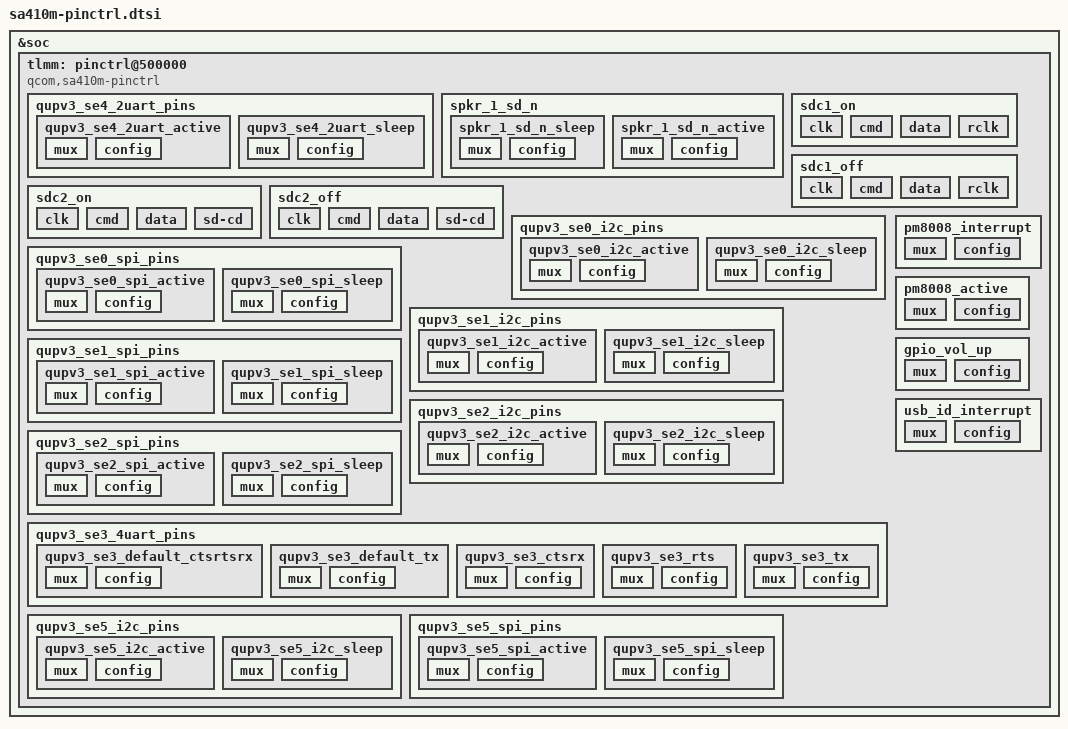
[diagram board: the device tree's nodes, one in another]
&soc {
	tlmm: pinctrl@500000 {
		compatible = "qcom,sa410m-pinctrl";
		reg = <0x500000 0x300000>;
		interrupts = <GIC_SPI 227 IRQ_TYPE_LEVEL_HIGH>;
		gpio-controller;
		#gpio-cells = <2>;
		interrupt-controller;
		#interrupt-cells = <2>;
		wakeup-parent = <&wakegic>;

		qupv3_se4_2uart_pins: qupv3_se4_2uart_pins {
			qupv3_se4_2uart_active: qupv3_se4_2uart_active {
				mux {
					pins = "gpio12", "gpio13";
					function = "qup4";
				};

				config {
					pins = "gpio12", "gpio13";
					drive-strength = <2>;
					bias-disable;
				};
			};

			qupv3_se4_2uart_sleep: qupv3_se4_2uart_sleep {
				mux {
					pins = "gpio12", "gpio13";
					function = "gpio";
				};

				config {
					pins = "gpio12", "gpio13";
					drive-strength = <2>;
					bias-pull-down;
				};
			};
		};

		/* WSA speaker reset pin1 */
		spkr_1_sd_n {
			spkr_1_sd_n_sleep: spkr_1_sd_n_sleep {
				mux {
					pins = "gpio106";
					function = "gpio";
				};

				config {
					pins = "gpio106";
					drive-strength = <2>;   /* 2 mA */
					bias-pull-down;
					input-enable;
				};
			};

			spkr_1_sd_n_active: spkr_1_sd_n_active {
				mux {
					pins = "gpio106";
					function = "gpio";
				};

				config {
					pins = "gpio106";
					drive-strength = <16>;   /* 16 mA */
					bias-disable;
					output-high;
				};
			};
		};

		/* SDC pin type */
		sdc1_on: sdc1_on {
			clk {
				pins = "sdc1_clk";
				bias-disable;
				drive-strength = <16>;
			};

			cmd {
				pins = "sdc1_cmd";
				bias-pull-up;
				drive-strength = <10>;
			};

			data {
				pins = "sdc1_data";
				bias-pull-up;
				drive-strength = <10>;
			};

			rclk {
				pins = "sdc1_rclk";
				bias-pull-down;
			};
		};

		sdc1_off: sdc1_off {
			clk {
				pins = "sdc1_clk";
				bias-disable;
				drive-strength = <2>;
			};

			cmd {
				pins = "sdc1_cmd";
				bias-pull-up;
				drive-strength = <2>;
			};

			data {
				pins = "sdc1_data";
				bias-pull-up;
				drive-strength = <2>;
			};

			rclk {
				pins = "sdc1_rclk";
				bias-pull-down;
			};
		};

		sdc2_on: sdc2_on {
			clk {
				pins = "sdc2_clk";
				bias-disable;
				drive-strength = <16>;
			};

			cmd {
				pins = "sdc2_cmd";
				bias-pull-up;
				drive-strength = <10>;
			};

			data {
				pins = "sdc2_data";
				bias-pull-up;
				drive-strength = <10>;
			};

			sd-cd {
				pins = "gpio88";
				bias-pull-up;
				drive-strength = <2>;
			};
		};

		sdc2_off: sdc2_off {
			clk {
				pins = "sdc2_clk";
				bias-disable;
				drive-strength = <2>;
			};

			cmd {
				pins = "sdc2_cmd";
				bias-pull-up;
				drive-strength = <2>;
			};

			data {
				pins = "sdc2_data";
				bias-pull-up;
				drive-strength = <2>;
			};

			sd-cd {
				pins = "gpio88";
				bias-disable;
				drive-strength = <2>;
			};
		};

		qupv3_se0_i2c_pins: qupv3_se0_i2c_pins {
			qupv3_se0_i2c_active: qupv3_se0_i2c_active {
				mux {
					pins = "gpio0", "gpio1";
					function = "qup0";
				};

				config {
					pins = "gpio0", "gpio1";
					drive-strength = <2>;
					bias-pull-up;
				};
			};

			qupv3_se0_i2c_sleep: qupv3_se0_i2c_sleep {
				mux {
					pins = "gpio0", "gpio1";
					function = "gpio";
				};

				config {
					pins = "gpio0", "gpio1";
					drive-strength = <2>;
					bias-disable;
				};
			};
		};

		qupv3_se0_spi_pins: qupv3_se0_spi_pins {
			qupv3_se0_spi_active: qupv3_se0_spi_active {
				mux {
					pins = "gpio0", "gpio1",
							"gpio2", "gpio3";
					function = "qup0";
				};

				config {
					pins = "gpio0", "gpio1",
							"gpio2", "gpio3";
					drive-strength = <6>;
					bias-disable;
				};
			};

			qupv3_se0_spi_sleep: qupv3_se0_spi_sleep {
				mux {
					pins = "gpio0", "gpio1",
							"gpio2", "gpio3";
					function = "gpio";
				};

				config {
					pins = "gpio0", "gpio1",
							"gpio2", "gpio3";
					drive-strength = <6>;
					bias-disable;
				};
			};
		};

		qupv3_se1_i2c_pins: qupv3_se1_i2c_pins {
			qupv3_se1_i2c_active: qupv3_se1_i2c_active {
				mux {
					pins = "gpio4", "gpio5";
					function = "qup1";
				};

				config {
					pins = "gpio4", "gpio5";
					drive-strength = <2>;
					bias-pull-up;
				};
			};

			qupv3_se1_i2c_sleep: qupv3_se1_i2c_sleep {
				mux {
					pins = "gpio4", "gpio5";
					function = "gpio";
				};

				config {
					pins = "gpio4", "gpio5";
					drive-strength = <2>;
					bias-disable;
				};
			};
		};

		qupv3_se1_spi_pins: qupv3_se1_spi_pins {
			qupv3_se1_spi_active: qupv3_se1_spi_active {
				mux {
					pins = "gpio4", "gpio5",
							"gpio69", "gpio70";
					function = "qup1";
				};

				config {
					pins = "gpio4", "gpio5",
							"gpio69", "gpio70";
					drive-strength = <6>;
					bias-disable;
				};
			};

			qupv3_se1_spi_sleep: qupv3_se1_spi_sleep {
				mux {
					pins = "gpio4", "gpio5",
							"gpio69", "gpio70";
					function = "gpio";
				};

				config {
					pins = "gpio4", "gpio5",
							"gpio69", "gpio70";
					drive-strength = <6>;
					bias-disable;
				};
			};
		};

		qupv3_se2_i2c_pins: qupv3_se2_i2c_pins {
			qupv3_se2_i2c_active: qupv3_se2_i2c_active {
				mux {
					pins = "gpio6", "gpio7";
					function = "qup2";
				};

				config {
					pins = "gpio6", "gpio7";
					drive-strength = <2>;
					bias-pull-up;
				};
			};

			qupv3_se2_i2c_sleep: qupv3_se2_i2c_sleep {
				mux {
					pins = "gpio6", "gpio7";
					function = "gpio";
				};

				config {
					pins = "gpio6", "gpio7";
					drive-strength = <2>;
					bias-disable;
				};
			};
		};

		qupv3_se2_spi_pins: qupv3_se2_spi_pins {
			qupv3_se2_spi_active: qupv3_se2_spi_active {
				mux {
					pins = "gpio6", "gpio7",
							"gpio71", "gpio80";
					function = "qup2";
				};

				config {
					pins = "gpio6", "gpio7",
							"gpio71", "gpio80";
					drive-strength = <6>;
					bias-disable;
				};
			};

			qupv3_se2_spi_sleep: qupv3_se2_spi_sleep {
				mux {
					pins = "gpio6", "gpio7",
							"gpio71", "gpio80";
					function = "gpio";
				};

				config {
					pins = "gpio6", "gpio7",
							"gpio71", "gpio80";
					drive-strength = <6>;
					bias-disable;
				};
			};
		};

		qupv3_se3_4uart_pins: qupv3_se3_4uart_pins {
			qupv3_se3_default_ctsrtsrx:
				qupv3_se3_default_ctsrtsrx {
				mux {
					pins = "gpio8", "gpio9", "gpio11";
					function = "gpio";
				};

				config {
					pins = "gpio8", "gpio9", "gpio11";
					drive-strength = <2>;
					bias-pull-down;
				};
			};

			qupv3_se3_default_tx:
				qupv3_se3_default_tx {
				mux {
					pins = "gpio10";
					function = "gpio";
				};

				config {
					pins = "gpio10";
					drive-strength = <2>;
					bias-pull-up;
				};
			};

			qupv3_se3_ctsrx: qupv3_se3_ctsrx {
				mux {
					pins = "gpio8", "gpio11";
					function = "qup3";
				};

				config {
					pins = "gpio8", "gpio11";
					drive-strength = <2>;
					bias-disable;
				};
			};

			qupv3_se3_rts: qupv3_se3_rts {
				mux {
					pins = "gpio9";
					function = "qup3";
				};

				config {
					pins = "gpio9";
					drive-strength = <2>;
					bias-pull-down;
				};
			};

			qupv3_se3_tx: qupv3_se3_tx {
				mux {
					pins = "gpio10";
					function = "qup3";
				};

				config {
					pins = "gpio10";
					drive-strength = <2>;
					bias-pull-up;
				};
			};
		};

		qupv3_se5_i2c_pins: qupv3_se5_i2c_pins {
			qupv3_se5_i2c_active: qupv3_se5_i2c_active {
				mux {
					pins = "gpio14", "gpio15";
					function = "qup5";
				};

				config {
					pins = "gpio14", "gpio15";
					drive-strength = <2>;
					bias-pull-up;
				};
			};

			qupv3_se5_i2c_sleep: qupv3_se5_i2c_sleep {
				mux {
					pins = "gpio14", "gpio15";
					function = "gpio";
				};

				config {
					pins = "gpio14", "gpio15";
					drive-strength = <2>;
					bias-disable;
				};
			};
		};

		qupv3_se5_spi_pins: qupv3_se5_spi_pins {
			qupv3_se5_spi_active: qupv3_se5_spi_active {
				mux {
					pins = "gpio14", "gpio15",
							"gpio16", "gpio17";
					function = "qup5";
				};

				config {
					pins = "gpio14", "gpio15",
							"gpio16", "gpio17";
					drive-strength = <6>;
					bias-disable;
				};
			};

			qupv3_se5_spi_sleep: qupv3_se5_spi_sleep {
				mux {
					pins = "gpio14", "gpio15",
							"gpio16", "gpio17";
					function = "gpio";
				};

				config {
					pins = "gpio14", "gpio15",
							"gpio16", "gpio17";
					drive-strength = <6>;
					bias-disable;
				};
			};
		};

		pm8008_interrupt: pm8008_interrupt {
			mux {
				pins = "gpio25";
				function = "gpio";
			};

			config {
				pins = "gpio25";
				bias-disable;
				input-enable;
			};
		};

		pm8008_active: pm8008_active {
			mux {
				pins = "gpio26";
				function = "gpio";
			};

			config {
				pins = "gpio26";
				bias-pull-up;
				output-high;
				drive-strength = <2>;
			};
		};

		gpio_vol_up: gpio_vol_up {
			mux {
				pins = "gpio96";
				function = "gpio";
			};

			config {
				pins = "gpio96";
				drive-strength = <2>;
				bias-pull-up;
				input-enable;
			};
		};

		usb_id_interrupt: usb_id_interrupt {
			mux {
				pins = "gpio89";
				function = "gpio";
			};

			config {
				pins = "gpio89";
				bias-pull-up;
				input-enable;
			};
		};
	};
};
